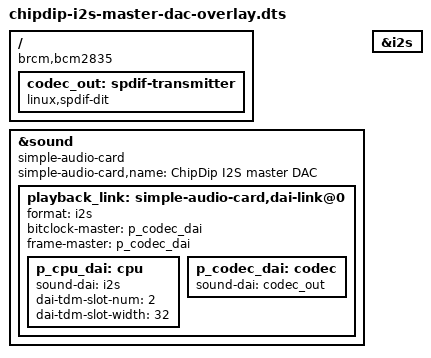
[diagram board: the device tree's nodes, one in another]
/*
 * Device Tree overlay for ChipDip I2S master DAC
 */

/dts-v1/;
/plugin/;

/ {
    compatible = "brcm,bcm2835";
    fragment@0 {
        target = <&sound>;
        __overlay__ {
            compatible = "simple-audio-card";
            simple-audio-card,name = "ChipDip I2S master DAC";
            status="okay";
            playback_link: simple-audio-card,dai-link@0 {
                format = "i2s";
		bitclock-master = <&p_codec_dai>;
                frame-master = <&p_codec_dai>;
                p_cpu_dai: cpu {
                        sound-dai = <&i2s>;
			dai-tdm-slot-num = <2>;
			dai-tdm-slot-width = <32>;
				};

                p_codec_dai: codec {
                        sound-dai = <&codec_out>;
                };
            };
        };
    }; 

    fragment@1 {
        target-path = "/";
        __overlay__ {
            codec_out: spdif-transmitter {
                #address-cells = <0>;
                #size-cells = <0>;
                #sound-dai-cells = <0>;
                compatible = "linux,spdif-dit";
                status = "okay";
            };
        };
    };
 
    fragment@2 {
        target = <&i2s>;
        __overlay__ {
            #sound-dai-cells = <0>;
            status = "okay";
        };
    };
}; 
